VERSION ""

NS_ :

BS_:

BU_: XXX

BO_ 85 CID_FULLDH: 8 XXX
 SG_ sig_katkzb : 40|1@1+ (1,0) [0|1] "" XXX
 SG_ sig_aukbja : 56|8@1+ (1,0) [0|255] "" XXX

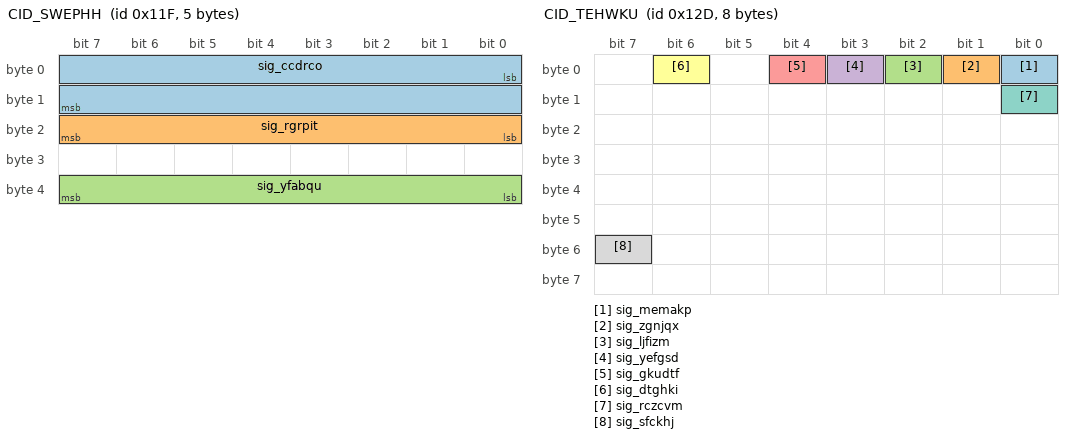
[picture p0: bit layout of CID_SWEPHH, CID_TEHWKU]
BO_ 287 CID_SWEPHH: 5 XXX
 SG_ sig_ccdrco : 0|16@1- (0.1,0) [-450|450] "" XXX
 SG_ sig_rgrpit : 16|8@1+ (4,0) [0|1020] "" XXX
 SG_ sig_yfabqu : 32|8@1+ (1,0) [0|255] "" XXX

BO_ 289 CID_AKYQOS: 8 XXX
 SG_ sig_qdwkuw : 0|12@1+ (1,0) [0|255] "" XXX

BO_ 301 CID_TEHWKU: 8 XXX
 SG_ sig_memakp : 0|1@0+ (1,0) [0|1] "" XXX
 SG_ sig_zgnjqx : 1|1@0+ (1,0) [0|1] "" XXX
 SG_ sig_ljfizm : 2|1@0+ (1,0) [0|1] "" XXX
 SG_ sig_yefgsd : 3|1@0+ (1,0) [0|1] "" XXX
 SG_ sig_gkudtf : 4|1@0+ (1,0) [0|1] "" XXX
 SG_ sig_dtghki : 6|1@0+ (1,0) [0|1] "" XXX
 SG_ sig_rczcvm : 8|1@0+ (1,0) [0|1] "" XXX
 SG_ sig_sfckhj : 55|1@0+ (1,0) [0|1] "" XXX

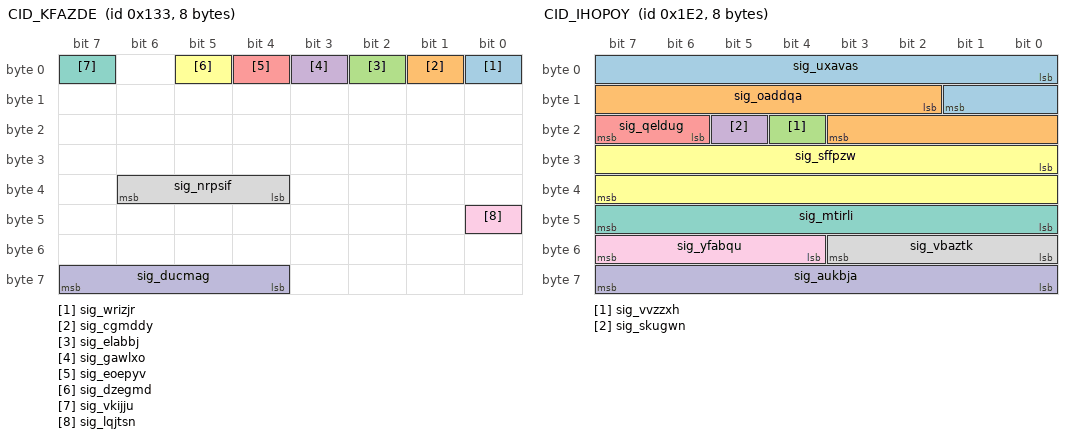
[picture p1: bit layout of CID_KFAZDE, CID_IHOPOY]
BO_ 307 CID_KFAZDE: 8 XXX
 SG_ sig_wrizjr : 0|1@0+ (1,0) [0|1] "" XXX
 SG_ sig_cgmddy : 1|1@1+ (1,0) [0|1] "" XXX
 SG_ sig_elabbj : 2|1@1+ (1,0) [0|1] "" XXX
 SG_ sig_gawlxo : 3|1@1+ (1,0) [0|1] "" XXX
 SG_ sig_eoepyv : 4|1@0+ (1,0) [0|1] "" XXX
 SG_ sig_dzegmd : 5|1@0+ (1,0) [0|1] "" XXX
 SG_ sig_vkijju : 7|1@0+ (1,0) [0|1] "" XXX
 SG_ sig_nrpsif : 36|3@1+ (1,0) [0|7] "" XXX
 SG_ sig_lqjtsn : 40|1@0+ (1,0) [0|1] "" XXX
 SG_ sig_ducmag : 63|4@0+ (1,0) [0|15] "" XXX

BO_ 482 CID_IHOPOY: 8 XXX
 SG_ sig_uxavas : 0|10@1- (0.01,0) [0|5] "" XXX
 SG_ sig_oaddqa : 10|10@1- (0.01,0) [-5|0] "" XXX
 SG_ sig_vvzzxh : 20|1@0+ (1,0) [0|1] "" XXX
 SG_ sig_skugwn : 21|1@0+ (1,0) [0|1] "" XXX
 SG_ sig_qeldug : 22|2@1+ (1,0) [0|1] "" XXX
 SG_ sig_sffpzw : 24|16@1- (0.1,0) [-780|779.9] "" XXX
 SG_ sig_mtirli : 47|8@0+ (1,0) [0|255] "" XXX
 SG_ sig_vbaztk : 48|4@1+ (1,0) [0|15] "" XXX
 SG_ sig_yfabqu : 52|4@1+ (1,0) [0|15] "" XXX
 SG_ sig_aukbja : 56|8@1+ (1,0) [0|255] "" XXX

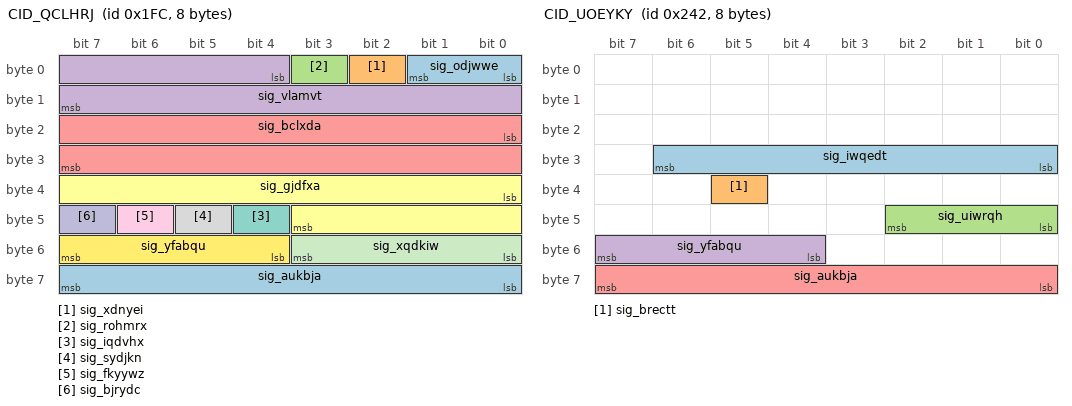
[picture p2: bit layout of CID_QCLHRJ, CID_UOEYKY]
BO_ 508 CID_QCLHRJ: 8 XXX
 SG_ sig_odjwwe : 0|2@1+ (1,0) [0|1] "" XXX
 SG_ sig_xdnyei : 2|1@1+ (1,0) [0|1] "" XXX
 SG_ sig_rohmrx : 3|1@0+ (1,0) [0|1] "" XXX
 SG_ sig_vlamvt : 4|12@1- (1,0) [-2048|2047] "" XXX
 SG_ sig_bclxda : 16|16@1- (0.1,0) [-780|779.9] "Deg" XXX
 SG_ sig_gjdfxa : 32|12@1- (0.01,0) [0|63] "" XXX
 SG_ sig_iqdvhx : 44|1@0+ (1,0) [0|1] "" XXX
 SG_ sig_sydjkn : 45|1@1+ (1,0) [0|255] "" XXX
 SG_ sig_fkyywz : 46|1@1+ (1,0) [0|1] "" XXX
 SG_ sig_bjrydc : 47|1@0+ (1,0) [0|3] "" XXX
 SG_ sig_xqdkiw : 48|4@1+ (1,0) [0|15] "" XXX
 SG_ sig_yfabqu : 52|4@1+ (1,0) [0|15] "" XXX
 SG_ sig_aukbja : 56|8@1+ (1,0) [0|255] "" XXX

BO_ 578 CID_UOEYKY: 8 XXX
 SG_ sig_iwqedt : 30|7@0+ (1,0) [0|127] "" XXX
 SG_ sig_brectt : 37|1@0+ (1,0) [0|1] "" XXX
 SG_ sig_uiwrqh : 40|3@1+ (1,0) [0|7] "" XXX
 SG_ sig_yfabqu : 55|4@0+ (1,0) [0|15] "" XXX
 SG_ sig_aukbja : 56|8@1+ (1,0) [0|255] "" XXX

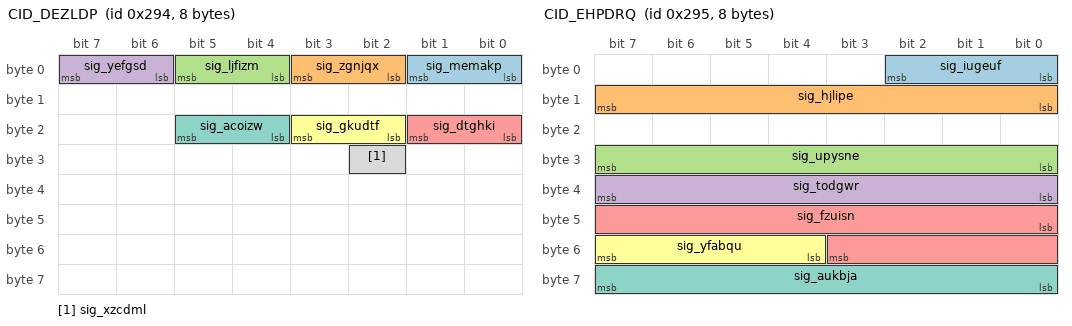
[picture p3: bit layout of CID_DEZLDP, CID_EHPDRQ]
BO_ 660 CID_DEZLDP: 8 XXX
 SG_ sig_memakp : 1|2@0+ (1,0) [0|3] "" XXX
 SG_ sig_zgnjqx : 3|2@0+ (1,0) [0|3] "" XXX
 SG_ sig_ljfizm : 5|2@0+ (1,0) [0|3] "" XXX
 SG_ sig_yefgsd : 7|2@0+ (1,0) [0|3] "" XXX
 SG_ sig_dtghki : 17|2@0+ (1,0) [0|3] "" XXX
 SG_ sig_gkudtf : 19|2@0+ (1,0) [0|3] "" XXX
 SG_ sig_acoizw : 21|2@0+ (1,0) [0|3] "" XXX
 SG_ sig_xzcdml : 26|1@0+ (1,0) [0|1] "" XXX

BO_ 661 CID_EHPDRQ: 8 XXX
 SG_ sig_iugeuf : 2|3@0+ (1,0) [0|7] "" XXX
 SG_ sig_hjlipe : 15|8@0+ (1,0) [0|255] "" XXX
 SG_ sig_upysne : 31|8@0+ (1,0) [0|255] "" XXX
 SG_ sig_todgwr : 32|8@1+ (1,0) [0|255] "" XXX
 SG_ sig_fzuisn : 40|12@1+ (1,0) [0|255] "" XXX
 SG_ sig_yfabqu : 52|4@1+ (1,0) [0|15] "" XXX
 SG_ sig_aukbja : 63|8@0+ (1,0) [0|255] "" XXX

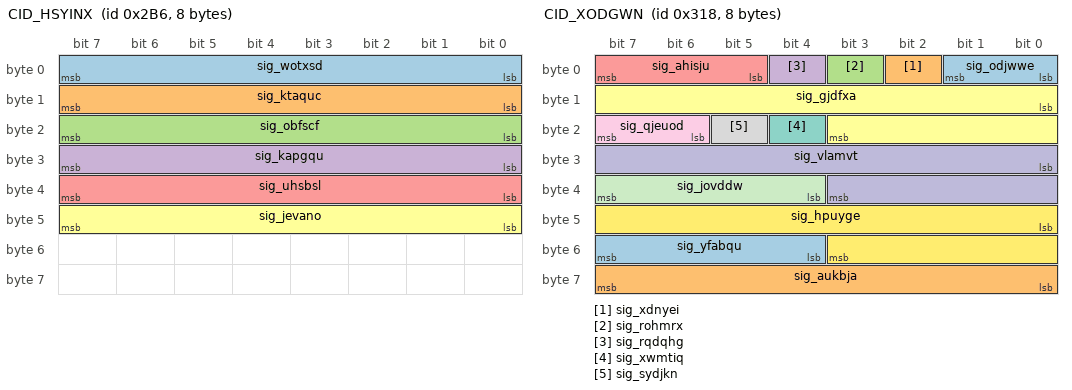
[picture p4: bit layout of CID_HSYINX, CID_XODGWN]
BO_ 694 CID_HSYINX: 8 XXX
 SG_ sig_wotxsd : 7|8@0+ (1,0) [0|255] "" XXX
 SG_ sig_ktaquc : 15|8@0+ (1,0) [0|255] "" XXX
 SG_ sig_obfscf : 23|8@0+ (1,0) [0|255] "" XXX
 SG_ sig_kapgqu : 31|8@0+ (1,0) [0|255] "" XXX
 SG_ sig_uhsbsl : 39|8@0+ (1,0) [0|255] "" XXX
 SG_ sig_jevano : 47|8@0+ (1,0) [0|255] "" XXX

BO_ 790 CID_UWNLRC: 8 XXX
 SG_ sig_qgegts : 3|4@0+ (1,0) [0|1] "" XXX
 SG_ sig_rxmcyr : 4|2@1+ (1,0) [0|3] "" XXX
 SG_ sig_nkaalt : 6|2@1+ (1,0) [0|3] "" XXX
 SG_ sig_kjqlto : 8|2@1+ (1,0) [0|3] "" XXX
 SG_ sig_tollce : 10|1@1+ (1,0) [0|1] "" XXX
 SG_ sig_xixtka : 11|4@1+ (1,0) [0|1] "" XXX
 SG_ sig_safibp : 15|1@0+ (1,0) [0|1] "" XXX
 SG_ sig_sffpzw : 16|11@1- (1,0) [-1024|1023] "" XXX
 SG_ sig_vvzzxh : 27|1@1+ (1,0) [0|1] "" XXX
 SG_ sig_skugwn : 28|1@1+ (1,0) [0|3] "" XXX
 SG_ sig_ajjwkb : 29|1@0+ (1,0) [0|1] "" XXX
 SG_ sig_sdhmcq : 30|1@0+ (1,0) [0|1] "" XXX
 SG_ sig_donfpn : 31|1@0+ (1,0) [0|1] "" XXX
 SG_ sig_chdfey : 32|2@1+ (1,0) [0|3] "" XXX
 SG_ sig_agcgra : 34|2@1+ (1,0) [0|3] "" XXX
 SG_ sig_kyesis : 36|4@1+ (1,0) [0|3] "" XXX
 SG_ sig_wgmhrk : 40|8@1+ (5,-5) [-5|1270] "" XXX
 SG_ sig_aykxcy : 49|2@0+ (1,0) [0|3] "" XXX
 SG_ sig_cecgxl : 51|2@0+ (1,0) [0|3] "" XXX
 SG_ sig_yfabqu : 52|4@1+ (1,0) [0|15] "" XXX
 SG_ sig_aukbja : 56|8@1+ (1,0) [0|15] "" XXX

BO_ 792 CID_XODGWN: 8 XXX
 SG_ sig_odjwwe : 0|2@1+ (1,0) [0|1] "" XXX
 SG_ sig_xdnyei : 2|1@1+ (1,0) [0|1] "" XXX
 SG_ sig_rohmrx : 3|1@1+ (1,0) [0|1] "" XXX
 SG_ sig_rqdqhg : 4|1@1+ (1,0) [0|1] "" XXX
 SG_ sig_ahisju : 5|3@1+ (1,0) [0|1] "" XXX
 SG_ sig_gjdfxa : 8|12@1- (1,0) [-2048|2047] "" XXX
 SG_ sig_xwmtiq : 20|1@1+ (1,0) [0|1] "" XXX
 SG_ sig_sydjkn : 21|1@1+ (1,0) [0|1] "" XXX
 SG_ sig_qjeuod : 22|2@1+ (1,0) [0|15] "" XXX
 SG_ sig_vlamvt : 24|12@1- (1,0) [-2048|2047] "" XXX
 SG_ sig_jovddw : 36|4@1+ (1,0) [0|15] "" XXX
 SG_ sig_hpuyge : 40|12@1+ (1,0) [0|4095] "" XXX
 SG_ sig_yfabqu : 52|4@1+ (1,0) [0|15] "" XXX
 SG_ sig_aukbja : 56|8@1+ (1,0) [0|255] "" XXX

BO_ 813 CID_AQDRZA: 8 XXX
 SG_ sig_oyjxll : 0|9@1+ (0.5,0) [0|255.5] "" XXX
 SG_ sig_umrqus : 9|1@1+ (1,0) [0|1] "" XXX
 SG_ sig_ygtlmu : 10|3@1+ (1,0) [0|7] "" XXX
 SG_ sig_ftrjhb : 13|3@1+ (1,0) [0|7] "" XXX
 SG_ sig_doykua : 16|1@1+ (1,0) [0|1] "" XXX
 SG_ sig_baxvtj : 17|1@1+ (1,0) [0|1] "" XXX
 SG_ sig_rohmrx : 18|1@1+ (1,0) [0|1] "" XXX
 SG_ sig_qvhhoi : 19|3@1+ (1,0) [0|1] "" XXX
 SG_ sig_msdzex : 22|1@0+ (1,0) [0|1] "" XXX
 SG_ sig_vxkgeu : 23|1@0+ (1,0) [0|1] "" XXX
 SG_ sig_kjqlto : 24|1@1+ (1,0) [0|1] "" XXX
 SG_ sig_unwrix : 25|7@1+ (1,0) [0|127] "" XXX
 SG_ sig_nkwzku : 32|4@1+ (1,0) [0|15] "" XXX
 SG_ sig_ydiaza : 36|12@1+ (1,0) [0|4095] "" XXX
 SG_ sig_yfabqu : 48|4@1+ (1,0) [0|15] "" XXX
 SG_ sig_loeoah : 55|4@0+ (1,0) [0|15] "" XXX
 SG_ sig_aukbja : 56|8@1+ (1,0) [0|255] "" XXX

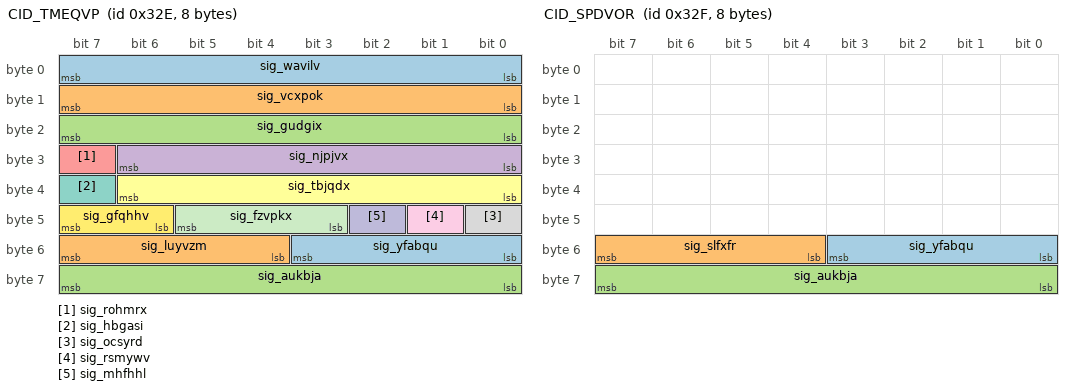
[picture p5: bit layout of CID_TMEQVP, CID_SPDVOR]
BO_ 814 CID_TMEQVP: 8 XXX
 SG_ sig_wavilv : 0|8@1+ (0.05,-5) [-100|155] "" XXX
 SG_ sig_vcxpok : 8|8@1+ (0.05,-5) [0|1.26] "" XXX
 SG_ sig_gudgix : 16|8@1+ (0.05,-5) [0|1.26] "" XXX
 SG_ sig_njpjvx : 24|7@1+ (0.2,0) [0|12.7] "" XXX
 SG_ sig_rohmrx : 31|1@0+ (1,0) [0|1] "" XXX
 SG_ sig_tbjqdx : 32|7@1+ (0.2,-16) [0|12.7] "" XXX
 SG_ sig_hbgasi : 39|1@0+ (1,0) [0|1] "" XXX
 SG_ sig_ocsyrd : 40|1@0+ (1,0) [0|1] "" XXX
 SG_ sig_rsmywv : 41|1@0+ (1,0) [0|1] "" XXX
 SG_ sig_mhfhhl : 42|1@1+ (1,0) [0|3] "" XXX
 SG_ sig_fzvpkx : 45|3@0+ (1,0) [0|1] "" XXX
 SG_ sig_gfqhhv : 46|2@1+ (1,0) [0|3] "" XXX
 SG_ sig_yfabqu : 48|4@1+ (1,0) [0|15] "" XXX
 SG_ sig_luyvzm : 55|4@0+ (1,0) [0|15] "" XXX
 SG_ sig_aukbja : 56|8@1+ (1,0) [0|255] "" XXX

BO_ 815 CID_SPDVOR: 8 XXX
 SG_ sig_yfabqu : 48|4@1+ (1,0) [0|15] "" XXX
 SG_ sig_slfxfr : 55|4@0+ (1,0) [0|15] "" XXX
 SG_ sig_aukbja : 56|8@1+ (1,0) [0|255] "" XXX

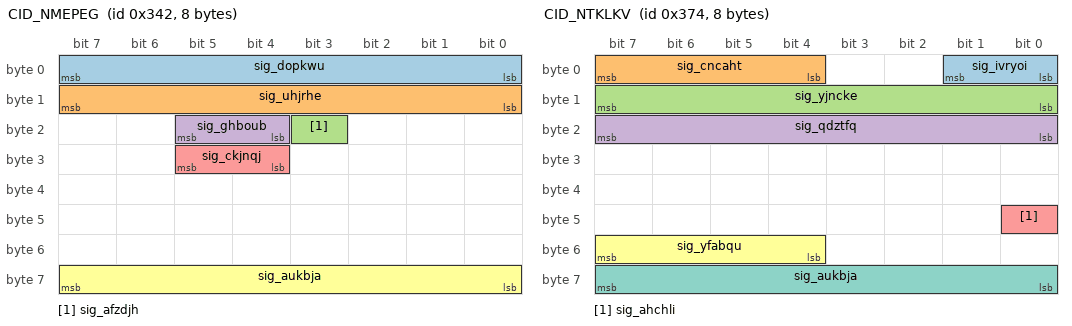
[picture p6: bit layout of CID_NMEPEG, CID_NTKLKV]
BO_ 834 CID_NMEPEG: 8 XXX
 SG_ sig_dopkwu : 0|8@1+ (0.01,0) [0|2.55] "" XXX
 SG_ sig_uhjrhe : 8|8@1+ (0.01,0) [0|2.55] "" XXX
 SG_ sig_afzdjh : 19|1@1+ (1,0) [0|1] "" XXX
 SG_ sig_ghboub : 20|2@1+ (1,0) [0|255] "" XXX
 SG_ sig_ckjnqj : 28|2@1+ (1,0) [0|1] "" XXX
 SG_ sig_aukbja : 56|8@1+ (1,0) [0|255] "" XXX

BO_ 884 CID_NTKLKV: 8 XXX
 SG_ sig_ivryoi : 1|2@0+ (1,0) [0|3] "" XXX
 SG_ sig_cncaht : 7|4@0+ (1,0) [0|15] "" XXX
 SG_ sig_yjncke : 15|8@0+ (0.1,-12) [0|255] "" XXX
 SG_ sig_qdztfq : 23|8@0+ (1,-100) [0|255] "" XXX
 SG_ sig_ahchli : 40|1@0+ (1,0) [0|3] "" XXX
 SG_ sig_yfabqu : 52|4@1+ (1,0) [0|15] "" XXX
 SG_ sig_aukbja : 56|8@1+ (1,0) [0|255] "" XXX

BO_ 944 CID_PZLDQM: 8 XXX
 SG_ sig_kcgkti : 1|2@0+ (1,0) [0|3] "" XXX
 SG_ sig_zqhsnx : 2|1@0+ (1,0) [0|1] "" XXX
 SG_ sig_sqyvfx : 4|2@0+ (1,0) [0|3] "" XXX
 SG_ sig_pfjhwj : 5|1@0+ (1,0) [0|1] "" XXX
 SG_ sig_nlzevb : 6|1@0+ (1,0) [0|1] "" XXX
 SG_ sig_lwkkhp : 7|1@0+ (1,0) [0|1] "" XXX
 SG_ sig_tuxqet : 8|1@0+ (1,0) [0|1] "" XXX
 SG_ sig_eonouf : 11|3@0+ (1,0) [0|7] "" XXX
 SG_ sig_xuetad : 12|1@0+ (1,0) [0|1] "" XXX
 SG_ sig_agovdi : 14|2@0+ (1,0) [0|3] "" XXX
 SG_ sig_dhriok : 15|1@0+ (1,0) [0|1] "" XXX
 SG_ sig_ejjlog : 16|1@0+ (1,0) [0|1] "" XXX
 SG_ sig_fjsplz : 18|2@0+ (1,0) [0|3] "" XXX
 SG_ sig_kzygjr : 19|1@0+ (1,0) [0|1] "" XXX
 SG_ sig_vpzipd : 23|4@0+ (1,0) [0|15] "" XXX
 SG_ sig_oututz : 24|28@1+ (1,0) [0|268435455] "" XXX
 SG_ sig_yfabqu : 52|4@1+ (1,0) [0|15] "" XXX
 SG_ sig_aukbja : 56|8@1+ (1,0) [0|255] "" XXX

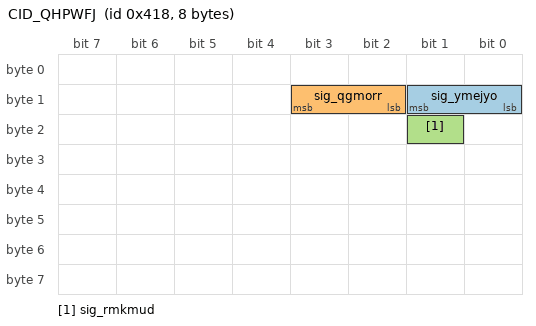
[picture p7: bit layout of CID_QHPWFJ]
BO_ 1048 CID_QHPWFJ: 8 XXX
 SG_ sig_ymejyo : 9|2@0+ (1,0) [0|1] "" XXX
 SG_ sig_qgmorr : 11|2@0+ (1,0) [0|1] "" XXX
 SG_ sig_rmkmud : 17|1@0+ (1,0) [0|1] "" XXX

VAL_ 578 sig_uiwrqh 4 "D" 2 "R" 3 "N" 1 "P";
VAL_ 790 sig_qgegts 11 "AutoFullBeamActive" 2 "AutoFullBeamInactive";
VAL_ 790 sig_rxmcyr 0 "GRAY" 1 "GREEN" 2 "YELLOW" 3 "RED";
VAL_ 790 sig_nkaalt 3 "ALARM_AND_LKA" 2 "LKA" 1 "ALARM" 0 "DISABLE";
VAL_ 790 sig_agcgra 0 "GRAY" 1 "GREEN" 2 "YELLOW" 3 "RED";
VAL_ 790 sig_aykxcy 0 "VIBRATION" 1 "AUDIO" 2 "AUDIO_AND_VIBRATION";
VAL_ 792 sig_odjwwe 0 "NotReady" 1 "Ready" 2 "Active" 3 "TemporaryFail";
VAL_ 813 sig_ygtlmu 4 "4BAR" 3 "3BAR" 2 "2BAR" 1 "1BAR";
VAL_ 813 sig_qvhhoi 0 "OFF" 2 "ACC_ON" 3 "ACC_ACTIVE" 5 "FORCE_ACCEL" 7 "ERROR";
VAL_ 813 sig_unwrix 36 "ACC_ERROR" 22 "OVERRIDE" 12 "ENGAGE" 8 "DISENGAGE" 20 "ACC_ON" 32 "ACC_OFF" 48 "CHECK_GEAR_D" 16 "FORCE_ACCEL" 0 "NONE";
VAL_ 814 sig_fzvpkx 0 "Off" 1 "Passive" 2 "StandBy" 3 "ActiveControl" 4 "BrakeOnly" 5 "Override" 6 "Standstill" 7 "Failure";
VAL_ 814 sig_gfqhhv 0 "Softoff" 1 "Fastoff" 2 "Immediateoff" 3 "Initial";
VAL_ 834 sig_ghboub 2 "SPORT" 1 "ECO" 0 "SNOW";
VAL_ 834 sig_ckjnqj 3 "HEV" 2 "FORCE_EV" 1 "EV";
VAL_ 944 sig_sqyvfx 0 "NOTPRESSED" 1 "DOWN_SETSPEED" 3 "UP_RESETSPEED";
